# mc200 register map
Registers are 32-bit, access not given, no defined reset value unless marked. A register's access mark holds for its fields unless they carry their own. Addresses are absolute; registers are grouped by the start of their names; [hi:lo] are bit positions; {n}, {i} and the like mark numbered series.

## UART0
0x46040000 UART0_RBR_THR_DLL
  [7:0] RBR_THR_DLL
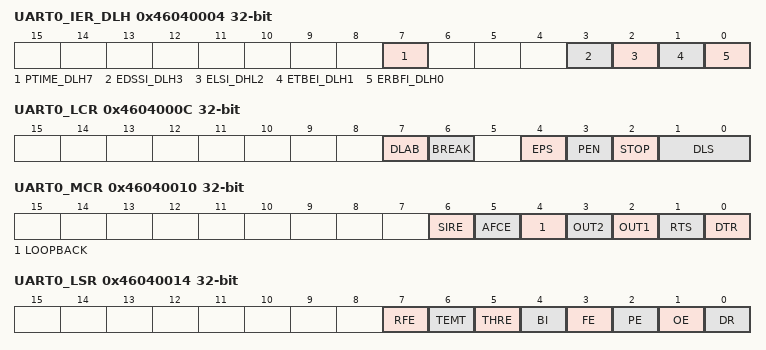
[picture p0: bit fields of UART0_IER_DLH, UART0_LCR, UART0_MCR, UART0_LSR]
0x46040004 UART0_IER_DLH
  [7] PTIME_DLH7, [3] EDSSI_DLH3, [2] ELSI_DHL2, [1] ETBEI_DLH1, [0] ERBFI_DLH0
0x46040008 UART0_IIR_FCR
  [31:0] DATA
0x4604000C UART0_LCR
  [7] DLAB, [6] BREAK, [4] EPS, [3] PEN, [2] STOP, [1:0] DLS
0x46040010 UART0_MCR
  [6] SIRE, [5] AFCE, [4] LOOPBACK, [3] OUT2, [2] OUT1, [1] RTS, [0] DTR
0x46040014 UART0_LSR
  [7] RFE, [6] TEMT, [5] THRE, [4] BI, [3] FE, [2] PE, [1] OE, [0] DR
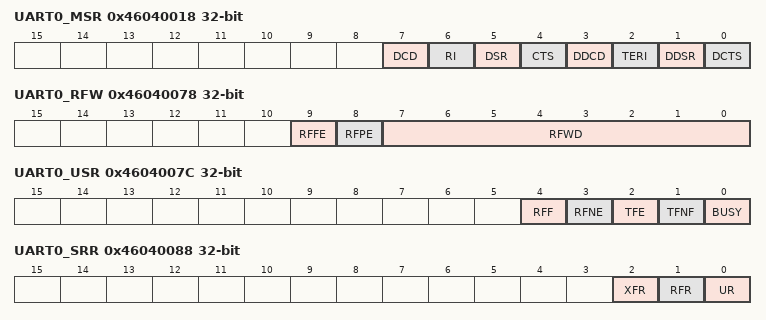
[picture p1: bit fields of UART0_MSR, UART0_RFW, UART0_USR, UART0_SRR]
0x46040018 UART0_MSR
  [7] DCD, [6] RI, [5] DSR, [4] CTS, [3] DDCD, [2] TERI, [1] DDSR, [0] DCTS
0x4604001C UART0_SCR
  [7:0] SCR
0x46040020 UART0_LPDLL
  [7:0] LPDLL
0x46040024 UART0_LPDLH
  [7:0] LPDLH
{0x46040030+4i} UART0_SRBR_STHR{i} (i=0..15)
  [7:0] SRBR_STHR{i}
0x46040070 UART0_FAR
  [0] SRBR_STHR
0x46040074 UART0_TFR
  [7:0] TFR
0x46040078 UART0_RFW
  [9] RFFE, [8] RFPE, [7:0] RFWD
0x4604007C UART0_USR
  [4] RFF, [3] RFNE, [2] TFE, [1] TFNF, [0] BUSY
0x46040080 UART0_TFL
  [4:0] TFL
0x46040084 UART0_RFL
  [4:0] RFL
0x46040088 UART0_SRR
  [2] XFR, [1] RFR, [0] UR
0x4604008C UART0_SRTS
  [0] SRTS
0x46040090 UART0_SBCR
  [0] SBCB
0x46040094 UART0_SDMAM
  [0] SDMAM
0x46040098 UART0_SFE
  [0] SFE
0x4604009C UART0_SRT
  [1:0] SRT
0x460400A0 UART0_STET
  [1:0] STET
0x460400A4 UART0_HTX
  [0] HTX
0x460400A8 UART0_DMASA
  [0] DMASA
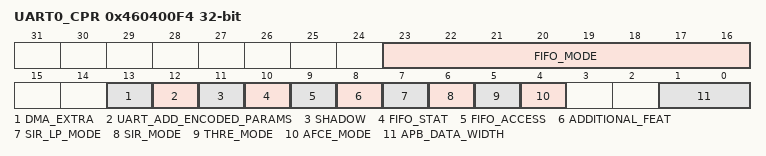
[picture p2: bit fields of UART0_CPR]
0x460400F4 UART0_CPR
  [23:16] FIFO_MODE, [13] DMA_EXTRA, [12] UART_ADD_ENCODED_PARAMS, [11] SHADOW, [10] FIFO_STAT, [9] FIFO_ACCESS, [8] ADDITIONAL_FEAT, [7] SIR_LP_MODE, [6] SIR_MODE, [5] THRE_MODE, [4] AFCE_MODE, [1:0] APB_DATA_WIDTH
0x460400F8 UART0_UCV
  [31:0] UART_COMPONENT_VERSION
0x460400FC UART0_CTR
  [31:0] PERIPHERAL_ID

## UART1
0x46050000 UART1_RBR_THR_DLL
  [7:0] RBR_THR_DLL
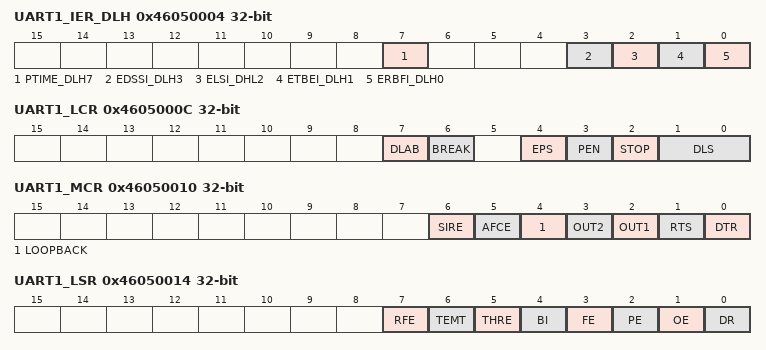
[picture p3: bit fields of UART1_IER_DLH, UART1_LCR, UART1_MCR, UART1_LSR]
0x46050004 UART1_IER_DLH
  [7] PTIME_DLH7, [3] EDSSI_DLH3, [2] ELSI_DHL2, [1] ETBEI_DLH1, [0] ERBFI_DLH0
0x46050008 UART1_IIR_FCR
  [31:0] DATA
0x4605000C UART1_LCR
  [7] DLAB, [6] BREAK, [4] EPS, [3] PEN, [2] STOP, [1:0] DLS
0x46050010 UART1_MCR
  [6] SIRE, [5] AFCE, [4] LOOPBACK, [3] OUT2, [2] OUT1, [1] RTS, [0] DTR
0x46050014 UART1_LSR
  [7] RFE, [6] TEMT, [5] THRE, [4] BI, [3] FE, [2] PE, [1] OE, [0] DR
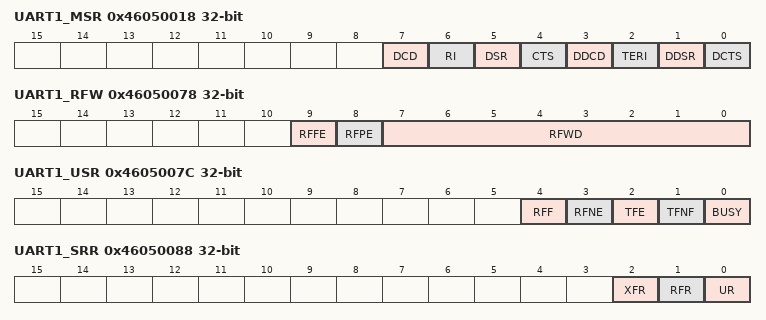
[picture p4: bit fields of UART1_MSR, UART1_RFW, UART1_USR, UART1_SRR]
0x46050018 UART1_MSR
  [7] DCD, [6] RI, [5] DSR, [4] CTS, [3] DDCD, [2] TERI, [1] DDSR, [0] DCTS
0x4605001C UART1_SCR
  [7:0] SCR
0x46050020 UART1_LPDLL
  [7:0] LPDLL
0x46050024 UART1_LPDLH
  [7:0] LPDLH
{0x46050030+4i} UART1_SRBR_STHR{i} (i=0..15)
  [7:0] SRBR_STHR{i}
0x46050070 UART1_FAR
  [0] SRBR_STHR
0x46050074 UART1_TFR
  [7:0] TFR
0x46050078 UART1_RFW
  [9] RFFE, [8] RFPE, [7:0] RFWD
0x4605007C UART1_USR
  [4] RFF, [3] RFNE, [2] TFE, [1] TFNF, [0] BUSY
0x46050080 UART1_TFL
  [4:0] TFL
0x46050084 UART1_RFL
  [4:0] RFL
0x46050088 UART1_SRR
  [2] XFR, [1] RFR, [0] UR
0x4605008C UART1_SRTS
  [0] SRTS
0x46050090 UART1_SBCR
  [0] SBCB
0x46050094 UART1_SDMAM
  [0] SDMAM
0x46050098 UART1_SFE
  [0] SFE
0x4605009C UART1_SRT
  [1:0] SRT
0x460500A0 UART1_STET
  [1:0] STET
0x460500A4 UART1_HTX
  [0] HTX
0x460500A8 UART1_DMASA
  [0] DMASA
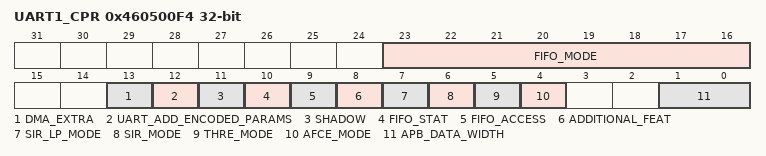
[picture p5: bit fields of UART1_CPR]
0x460500F4 UART1_CPR
  [23:16] FIFO_MODE, [13] DMA_EXTRA, [12] UART_ADD_ENCODED_PARAMS, [11] SHADOW, [10] FIFO_STAT, [9] FIFO_ACCESS, [8] ADDITIONAL_FEAT, [7] SIR_LP_MODE, [6] SIR_MODE, [5] THRE_MODE, [4] AFCE_MODE, [1:0] APB_DATA_WIDTH
0x460500F8 UART1_UCV
  [31:0] UART_COMPONENT_VERSION
0x460500FC UART1_CTR
  [31:0] PERIPHERAL_ID

## GPIO
{0x46060000+4i} GPIO_GPIO_GPLR_REG{i} (i=0..2)
  [31:0] GPLR_REG{i}
{0x4606000C+4i} GPIO_GPIO_GPDR_REG{i} (i=0..2)
  [31:0] GPDR_REG{i}
{0x46060018+4i} GPIO_GPIO_GPSR_REG{i} (i=0..2)
  [31:0] GPSR_REG{i}
{0x46060024+4i} GPIO_GPIO_GPCR_REG{i} (i=0..2)
  [31:0] GPCR_REG{i}
{0x46060030+4i} GPIO_GPIO_GRER_REG{i} (i=0..2)
  [31:0] GRER_REG{i}
{0x4606003C+4i} GPIO_GPIO_GFER_REG{i} (i=0..2)
  [31:0] GFER_REG{i}
{0x46060048+4i} GPIO_GPIO_GEDR_REG{i} (i=0..2)
  [31:0] GEDR_REG{i}
{0x46060054+4i} GPIO_GPIO_GSDR_REG{i} (i=0..2)
  [31:0] GSDR_REG{i}
{0x46060060+4i} GPIO_GPIO_GCDR_REG{i} (i=0..2)
  [31:0] GCDR_REG{i}
{0x4606006C+4i} GPIO_GPIO_GSRER_REG{i} (i=0..2)
  [31:0] GSRER_REG{i}
{0x46060078+4i} GPIO_GPIO_GCRER_REG{i} (i=0..2)
  [31:0] GCRER_REG{i}
{0x46060084+4i} GPIO_GPIO_GSFER_REG{i} (i=0..2)
  [31:0] GSFER_REG{i}
{0x46060090+4i} GPIO_GPIO_GCFER_REG{i} (i=0..2)
  [31:0] GCFER_REG{i}
{0x4606009C+4i} GPIO_APMASK_REG{i} (i=0..2)
  [31:0] APMASK_REG{i}
{0x460600F4+4i} GPIO_GPIO_GPLR_REG{i} (i=3..5)
  [31:0] GPLR_REG{i}
{0x46060100+4i} GPIO_GPIO_GPDR_REG{i} (i=3..5)
  [31:0] GPDR_REG{i}
{0x4606010C+4i} GPIO_GPIO_GPSR_REG{i} (i=3..5)
  [31:0] GPSR_REG{i}
{0x46060118+4i} GPIO_GPIO_GPCR_REG{i} (i=3..5)
  [31:0] GPCR_REG{i}
{0x46060124+4i} GPIO_GPIO_GRER_REG{i} (i=3..5)
  [31:0] GRER_REG{i}
{0x46060130+4i} GPIO_GPIO_GFER_REG{i} (i=3..5)
  [31:0] GFER_REG{i}
{0x4606013C+4i} GPIO_GPIO_GEDR_REG{i} (i=3..5)
  [31:0] GEDR_REG{i}
{0x46060148+4i} GPIO_GPIO_GSDR_REG{i} (i=3..5)
  [31:0] GSDR_REG{i}
{0x46060154+4i} GPIO_GPIO_GCDR_REG{i} (i=3..5)
  [31:0] GCDR_REG{i}
{0x46060160+4i} GPIO_GPIO_GSRER_REG{i} (i=3..5)
  [31:0] GSRER_REG{i}
{0x4606016C+4i} GPIO_GPIO_GCRER_REG{i} (i=3..5)
  [31:0] GCRER_REG{i}
{0x46060178+4i} GPIO_GPIO_GSFER_REG{i} (i=3..5)
  [31:0] GSFER_REG{i}
{0x46060184+4i} GPIO_GPIO_GCFER_REG{i} (i=3..5)
  [31:0] GCFER_REG{i}
{0x46060190+4i} GPIO_APMASK_REG{i} (i=3..5)
  [31:0] APMASK_REG{i}
